VERSION ""

NS_ :

BS_:

BU_: CAN_NODE_0 CAN_NODE_4 CAN_NODE_3 CAN_NODE_2 CAN_NODE_1 VCU VCU_CONFEDITOR

BO_ 1540 CAN_NODE_4: 8 CAN_NODE_4
 SG_ CAN_NODE_multiplexor M : 0|4@1+ (1,0) [0|0] "" Vector__XXX
 SG_ CAN_NODE_THERM_2 m2 : 8|8@1- (1,80) [-48|207] "C" Vector__XXX
 SG_ CAN_NODE_THERM_1 m2 : 16|8@1- (1,80) [-48|207] "C" Vector__XXX
 SG_ CAN_NODE_PD_9 m1 : 40|12@1+ (0.00402832031,0) [0|16.49597166945] "V" Vector__XXX
 SG_ CAN_NODE_PD_8 m1 : 28|12@1+ (0.00402832031,0) [0|16.49597166945] "V" Vector__XXX
 SG_ CAN_NODE_PD_7 m1 : 16|12@1+ (0.00402832031,0) [0|16.49597166945] "V" Vector__XXX
 SG_ CAN_NODE_PD_6 m1 : 4|12@1+ (0.00402832031,0) [0|16.49597166945] "V" Vector__XXX
 SG_ CAN_NODE_PD_5 m0 : 52|12@1+ (0.00402832031,0) [0|16.49597166945] "V" Vector__XXX
 SG_ CAN_NODE_PD_4 m0 : 40|12@1+ (0.00402832031,0) [0|16.49597166945] "V" Vector__XXX
 SG_ CAN_NODE_PD_3 m0 : 28|12@1+ (0.00402832031,0) [0|16.49597166945] "V" Vector__XXX
 SG_ CAN_NODE_PD_2 m0 : 16|12@1+ (0.00402832031,0) [0|16.49597166945] "V" Vector__XXX
 SG_ CAN_NODE_PD_10 m1 : 52|12@1+ (0.00402832031,0) [0|16.49597166945] "V" Vector__XXX
 SG_ CAN_NODE_PD_1 m0 : 4|12@1+ (0.00402832,0) [0|16.4959704] "V" Vector__XXX

BO_ 1539 CAN_NODE_3: 8 CAN_NODE_3
 SG_ CAN_NODE_multiplexor M : 0|4@1+ (1,0) [0|0] "" Vector__XXX
 SG_ CAN_NODE_THERM_2 m2 : 8|8@1- (1,80) [-48|207] "C" Vector__XXX
 SG_ CAN_NODE_THERM_1 m2 : 16|8@1- (1,80) [-48|207] "C" Vector__XXX
 SG_ CAN_NODE_PD_9 m1 : 40|12@1+ (0.00402832031,0) [0|16.49597166945] "V" Vector__XXX
 SG_ CAN_NODE_PD_8 m1 : 28|12@1+ (0.00402832031,0) [0|16.49597166945] "V" Vector__XXX
 SG_ CAN_NODE_PD_7 m1 : 16|12@1+ (0.00402832031,0) [0|16.49597166945] "V" Vector__XXX
 SG_ CAN_NODE_PD_6 m1 : 4|12@1+ (0.00402832031,0) [0|16.49597166945] "V" Vector__XXX
 SG_ CAN_NODE_PD_5 m0 : 52|12@1+ (0.00402832031,0) [0|16.49597166945] "V" Vector__XXX
 SG_ CAN_NODE_PD_4 m0 : 40|12@1+ (0.00402832031,0) [0|16.49597166945] "V" Vector__XXX
 SG_ CAN_NODE_PD_3 m0 : 28|12@1+ (0.00402832031,0) [0|16.49597166945] "V" Vector__XXX
 SG_ CAN_NODE_PD_2 m0 : 16|12@1+ (0.00402832031,0) [0|16.49597166945] "V" Vector__XXX
 SG_ CAN_NODE_PD_10 m1 : 52|12@1+ (0.00402832031,0) [0|16.49597166945] "V" Vector__XXX
 SG_ CAN_NODE_PD_1 m0 : 4|12@1+ (0.00402832,0) [0|16.4959704] "V" Vector__XXX

BO_ 1538 CAN_NODE_2: 8 CAN_NODE_2
 SG_ CAN_NODE_multiplexor M : 0|4@1+ (1,0) [0|0] "" Vector__XXX
 SG_ CAN_NODE_THERM_2 m2 : 8|8@1- (1,80) [-48|207] "C" Vector__XXX
 SG_ CAN_NODE_THERM_1 m2 : 16|8@1- (1,80) [-48|207] "C" Vector__XXX
 SG_ CAN_NODE_PD_9 m1 : 40|12@1+ (0.00402832031,0) [0|16.49597166945] "V" Vector__XXX
 SG_ CAN_NODE_PD_8 m1 : 28|12@1+ (0.00402832031,0) [0|16.49597166945] "V" Vector__XXX
 SG_ CAN_NODE_PD_7 m1 : 16|12@1+ (0.00402832031,0) [0|16.49597166945] "V" Vector__XXX
 SG_ CAN_NODE_PD_6 m1 : 4|12@1+ (0.00402832031,0) [0|16.49597166945] "V" Vector__XXX
 SG_ CAN_NODE_PD_5 m0 : 52|12@1+ (0.00402832031,0) [0|16.49597166945] "V" Vector__XXX
 SG_ CAN_NODE_PD_4 m0 : 40|12@1+ (0.00402832031,0) [0|16.49597166945] "V" Vector__XXX
 SG_ CAN_NODE_PD_3 m0 : 28|12@1+ (0.00402832031,0) [0|16.49597166945] "V" Vector__XXX
 SG_ CAN_NODE_PD_2 m0 : 16|12@1+ (0.00402832031,0) [0|16.49597166945] "V" Vector__XXX
 SG_ CAN_NODE_PD_10 m1 : 52|12@1+ (0.00402832031,0) [0|16.49597166945] "V" Vector__XXX
 SG_ CAN_NODE_PD_1 m0 : 4|12@1+ (0.00402832,0) [0|16.4959704] "V" Vector__XXX

BO_ 1537 CAN_NODE_1: 8 CAN_NODE_1
 SG_ CAN_NODE_multiplexor M : 0|4@1+ (1,0) [0|0] "" Vector__XXX
 SG_ CAN_NODE_THERM_2 m2 : 8|8@1- (1,80) [-48|207] "C" Vector__XXX
 SG_ CAN_NODE_THERM_1 m2 : 16|8@1- (1,80) [-48|207] "C" Vector__XXX
 SG_ CAN_NODE_PD_9 m1 : 40|12@1+ (0.00402832031,0) [0|16.49597166945] "V" Vector__XXX
 SG_ CAN_NODE_PD_8 m1 : 28|12@1+ (0.00402832031,0) [0|16.49597166945] "V" Vector__XXX
 SG_ CAN_NODE_PD_7 m1 : 16|12@1+ (0.00402832031,0) [0|16.49597166945] "V" Vector__XXX
 SG_ CAN_NODE_PD_6 m1 : 4|12@1+ (0.00402832031,0) [0|16.49597166945] "V" Vector__XXX
 SG_ CAN_NODE_PD_5 m0 : 52|12@1+ (0.00402832031,0) [0|16.49597166945] "V" Vector__XXX
 SG_ CAN_NODE_PD_4 m0 : 40|12@1+ (0.00402832031,0) [0|16.49597166945] "V" Vector__XXX
 SG_ CAN_NODE_PD_3 m0 : 28|12@1+ (0.00402832031,0) [0|16.49597166945] "V" Vector__XXX
 SG_ CAN_NODE_PD_2 m0 : 16|12@1+ (0.00402832031,0) [0|16.49597166945] "V" Vector__XXX
 SG_ CAN_NODE_PD_10 m1 : 52|12@1+ (0.00402832031,0) [0|16.49597166945] "V" Vector__XXX
 SG_ CAN_NODE_PD_1 m0 : 4|12@1+ (0.00402832,0) [0|16.4959704] "V" Vector__XXX

BO_ 1536 CAN_NODE_0: 8 CAN_NODE_0
 SG_ CAN_NODE_multiplexor M : 0|4@1+ (1,0) [0|0] "" Vector__XXX
 SG_ CAN_NODE_THERM_2 m2 : 8|8@1- (1,80) [-48|207] "C" Vector__XXX
 SG_ CAN_NODE_THERM_1 m2 : 16|8@1- (1,80) [-48|207] "C" Vector__XXX
 SG_ CAN_NODE_PD_9 m1 : 40|12@1+ (0.00402832031,0) [0|16.49597166945] "V" Vector__XXX
 SG_ CAN_NODE_PD_8 m1 : 28|12@1+ (0.00402832031,0) [0|16.49597166945] "V" Vector__XXX
 SG_ CAN_NODE_PD_7 m1 : 16|12@1+ (0.00402832031,0) [0|16.49597166945] "V" Vector__XXX
 SG_ CAN_NODE_PD_6 m1 : 4|12@1+ (0.00402832031,0) [0|16.49597166945] "V" Vector__XXX
 SG_ CAN_NODE_PD_5 m0 : 52|12@1+ (0.00402832031,0) [0|16.49597166945] "V" Vector__XXX
 SG_ CAN_NODE_PD_4 m0 : 40|12@1+ (0.00402832031,0) [0|16.49597166945] "V" Vector__XXX
 SG_ CAN_NODE_PD_3 m0 : 28|12@1+ (0.00402832031,0) [0|16.49597166945] "V" Vector__XXX
 SG_ CAN_NODE_PD_2 m0 : 16|12@1+ (0.00402832031,0) [0|16.49597166945] "V" Vector__XXX
 SG_ CAN_NODE_PD_10 m1 : 52|12@1+ (0.00402832031,0) [0|16.49597166945] "V" Vector__XXX
 SG_ CAN_NODE_PD_1 m0 : 4|12@1+ (0.00402832,0) [0|16.4959704] "V" Vector__XXX

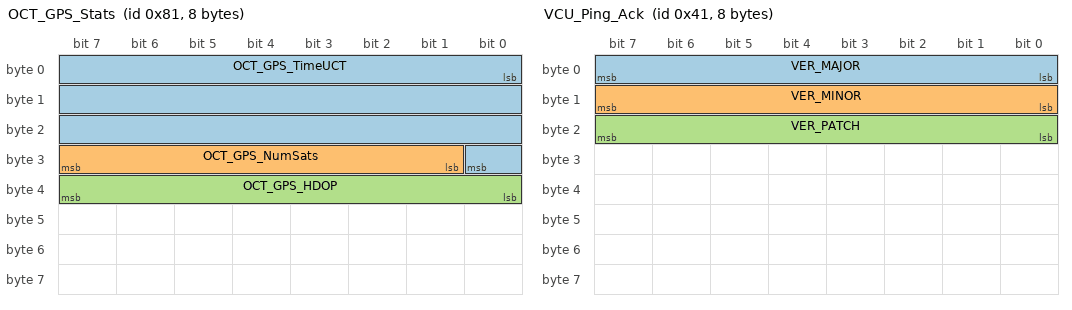
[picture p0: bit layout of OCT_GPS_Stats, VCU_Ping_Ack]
BO_ 129 OCT_GPS_Stats: 8 Vector__XXX
 SG_ OCT_GPS_TimeUCT : 0|25@1+ (0.01,0) [0|24000000] "" Vector__XXX
 SG_ OCT_GPS_NumSats : 25|7@1+ (1,0) [0|99] "" Vector__XXX
 SG_ OCT_GPS_HDOP : 32|8@1+ (1,0) [0|256] "" Vector__XXX

BO_ 128 OCT_GPS_LatLong: 8 Vector__XXX
 SG_ OCT_GPS_Longitude : 0|32@1- (0.0001,0) [0|1809999999] "" Vector__XXX
 SG_ OCT_GPS_Latitude : 32|31@1- (0.0001,0) [0|909999999] "" Vector__XXX

BO_ 64 VCU_Ping: 8 VCU_CONFEDITOR

BO_ 65 VCU_Ping_Ack: 8 VCU
 SG_ VER_MAJOR : 0|8@1+ (1,0) [0|0] ""  VCU_CONFEDITOR
 SG_ VER_MINOR : 8|8@1+ (1,0) [0|0] ""  VCU_CONFEDITOR
 SG_ VER_PATCH : 16|8@1+ (1,0) [0|0] ""  VCU_CONFEDITOR

BO_ 66 VCU_TS_On: 8 VCU

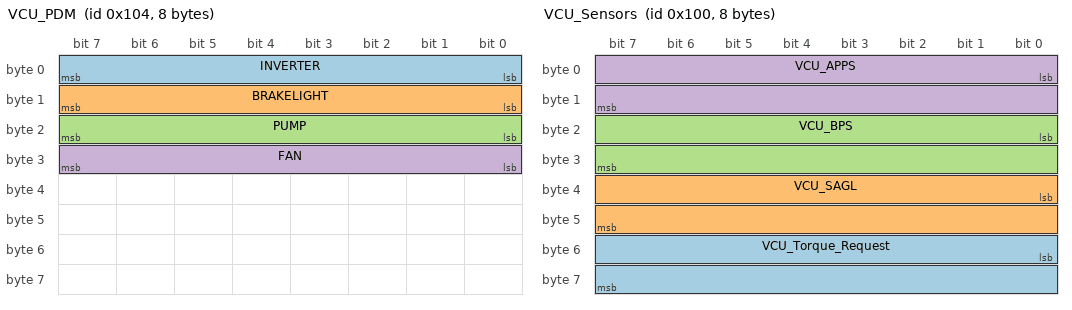
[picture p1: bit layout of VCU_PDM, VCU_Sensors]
BO_ 260 VCU_PDM: 8 Vector__XXX
 SG_ INVERTER : 0|8@1+ (1,0) [0|1] "On/Off" Vector__XXX
 SG_ BRAKELIGHT : 8|8@1+ (1,0) [0|1] "On/Off" Vector__XXX
 SG_ PUMP : 16|8@1+ (1,0) [0|1] "On/Off" Vector__XXX
 SG_ FAN : 24|8@1+ (1,0) [0|1] "On/Off" Vector__XXX

BO_ 256 VCU_Sensors: 8 Vector__XXX
 SG_ VCU_Torque_Request : 48|16@1+ (0.1,0) [0|6553.5] "Nm" Vector__XXX
 SG_ VCU_SAGL : 32|16@1+ (0.1,0) [0|100] "deg" Vector__XXX
 SG_ VCU_BPS : 16|16@1+ (0.1,0) [0|100] "" Vector__XXX
 SG_ VCU_APPS : 0|16@1+ (0.1,0) [0|100] "%" Vector__XXX

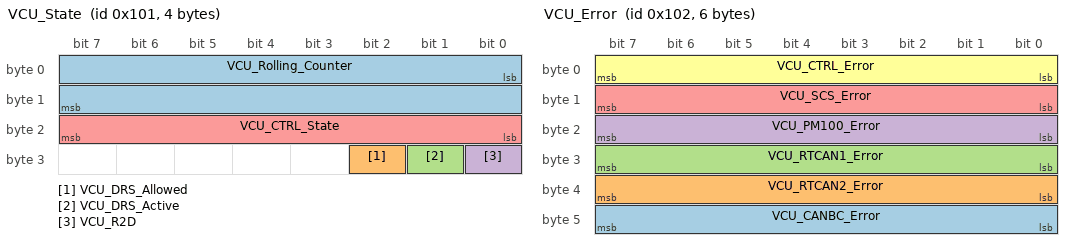
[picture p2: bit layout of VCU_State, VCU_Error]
BO_ 257 VCU_State: 4 Vector__XXX
 SG_ VCU_Rolling_Counter : 0|16@1+ (1,0) [0|65535] "" Vector__XXX
 SG_ VCU_DRS_Allowed : 26|1@1+ (1,0) [0|1] "" Vector__XXX
 SG_ VCU_DRS_Active : 25|1@1+ (1,0) [0|1] "" Vector__XXX
 SG_ VCU_R2D : 24|1@1+ (1,0) [0|1] "" Vector__XXX
 SG_ VCU_CTRL_State : 16|8@1+ (1,0) [0|255] "" Vector__XXX

BO_ 258 VCU_Error: 6 Vector__XXX
 SG_ VCU_CANBC_Error : 40|8@1+ (1,0) [0|255] "" Vector__XXX
 SG_ VCU_RTCAN2_Error : 32|8@1+ (1,0) [0|255] "" Vector__XXX
 SG_ VCU_RTCAN1_Error : 24|8@1+ (1,0) [0|255] "" Vector__XXX
 SG_ VCU_PM100_Error : 16|8@1+ (1,0) [0|255] "" Vector__XXX
 SG_ VCU_SCS_Error : 8|8@1+ (1,0) [0|255] "" Vector__XXX
 SG_ VCU_CTRL_Error : 0|8@1+ (1,0) [0|255] "" Vector__XXX

CM_ BU_ VCU "SUFST vehicle control unit";
CM_ BU_ VCU_CONFEDITOR "SUFST VCU configuration editor software";
CM_ BO_ 129 "Horizontal Dilution of Precision (HDOP), number of connected satellites, and UCT Time from satellites.";
CM_ BO_ 128 "Latitude and Longitude values in fixed point decimal format.";
CM_ BO_ 64 "Ping the VCU";
CM_ BO_ 65 "Response from VCU to a ping request";
CM_ BO_ 66 "Enable the TS with the PDU.";
CM_ BO_ 260 "Periodic messages from VCU to PDM";
BA_DEF_  "BusType" STRING ;
BA_DEF_ BO_  "OCT_PDU_ID" INT 0 0;
BA_DEF_ BO_  "OCT_ENABLE" ENUM  "False","True";
BA_DEF_DEF_  "BusType" "CAN";
BA_DEF_DEF_  "OCT_PDU_ID" 0;
BA_DEF_DEF_  "OCT_ENABLE" "False";
BA_ "OCT_PDU_ID" BO_ 129 8;
BA_ "OCT_ENABLE" BO_ 129 1;
BA_ "OCT_PDU_ID" BO_ 128 7;
BA_ "OCT_ENABLE" BO_ 128 1;
